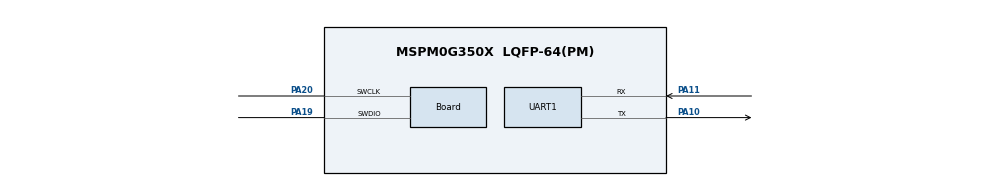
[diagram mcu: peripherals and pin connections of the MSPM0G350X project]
/**
 * @cliArgs --device "MSPM0G350X" --part "Default" --package "LQFP-64(PM)" --product "mspm0_sdk@2.02.00.05"
 * @versions {"tool":"1.21.0+3721"}
 */

/**
 * Import the modules used in this configuration.
 */
const ADC12  = scripting.addModule("/ti/driverlib/ADC12", {}, false);
const ADC121 = ADC12.addInstance();
const SYSCTL = scripting.addModule("/ti/driverlib/SYSCTL");
const UART   = scripting.addModule("/ti/driverlib/UART", {}, false);
const UART1  = UART.addInstance();

/**
 * Write custom configuration values to the imported modules.
 */
ADC121.$name                             = "ADC_VOLTAGE";
ADC121.sampClkDiv                        = "DL_ADC12_CLOCK_DIVIDE_8";
ADC121.repeatMode                        = true;
ADC121.adcMem0_name                      = "ADC_CH0";
ADC121.enabledInterrupts                 = ["DL_ADC12_INTERRUPT_MEM0_RESULT_LOADED"];
ADC121.powerDownMode                     = "DL_ADC12_POWER_DOWN_MODE_MANUAL";
ADC121.sampleTime0                       = "1us";
ADC121.peripheral.$assign                = "ADC0";
ADC121.peripheral.adcPin0.$assign        = "PA27";
ADC121.adcPin0Config.$name               = "ti_driverlib_gpio_GPIOPinGeneric0";
ADC121.adcPin0Config.hideOutputInversion = scripting.forceWrite(false);

const Board                       = scripting.addModule("/ti/driverlib/Board", {}, false);
Board.peripheral.$assign          = "DEBUGSS";
Board.peripheral.swclkPin.$assign = "PA20";
Board.peripheral.swdioPin.$assign = "PA19";

SYSCTL.peripheral.$assign = "SYSCTL";

UART1.$name                    = "UART_0";
UART1.peripheral.$assign       = "UART0";
UART1.peripheral.rxPin.$assign = "PA11";
UART1.peripheral.txPin.$assign = "PA10";
UART1.txPinConfig.$name        = "ti_driverlib_gpio_GPIOPinGeneric1";
UART1.rxPinConfig.$name        = "ti_driverlib_gpio_GPIOPinGeneric2";

const ProjectConfig              = scripting.addModule("/ti/project_config/ProjectConfig", {}, false);
ProjectConfig.migrationCondition = true;
